# HC32F334JATI register map
File version: 1.0
CPU: CM4 r0p1, little endian, MPU, FPU, 4 interrupt priority bits
Registers are 32-bit, read-write, reset 0x0 unless marked. A register's access mark holds for its fields unless they carry their own. Offsets are from the block's base; [hi:lo] are bit positions; {n}, {i} and the like mark numbered series.

## CRC
Base 0x40008C00
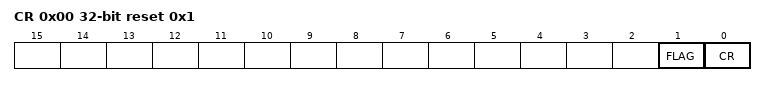
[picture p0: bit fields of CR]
0x00 CR reset 0x1
  [1] FLAG ro, [0] CR
0x04 RESLT
{0x80+4i} DAT{i} wo (i=0..31)

## CTC
Base 0x40049C00
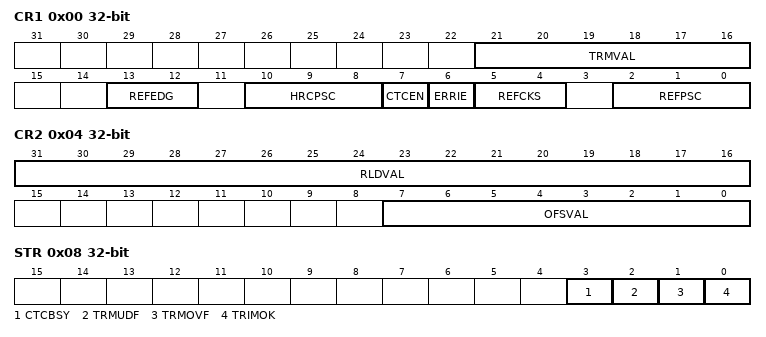
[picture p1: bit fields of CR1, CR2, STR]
0x00 CR1
  [21:16] TRMVAL, [13:12] REFEDG, [10:8] HRCPSC, [7] CTCEN, [6] ERRIE, [5:4] REFCKS, [2:0] REFPSC
0x04 CR2
  [31:16] RLDVAL, [7:0] OFSVAL
0x08 STR ro
  [3] CTCBSY, [2] TRMUDF, [1] TRMOVF, [0] TRIMOK
0x0C CNT 16-bit ro

## DAC1 — desc DAC
Base 0x40041000
Same registers: DAC2 0x40041400
0x00 DADR1 16-bit
0x02 DADR2 16-bit
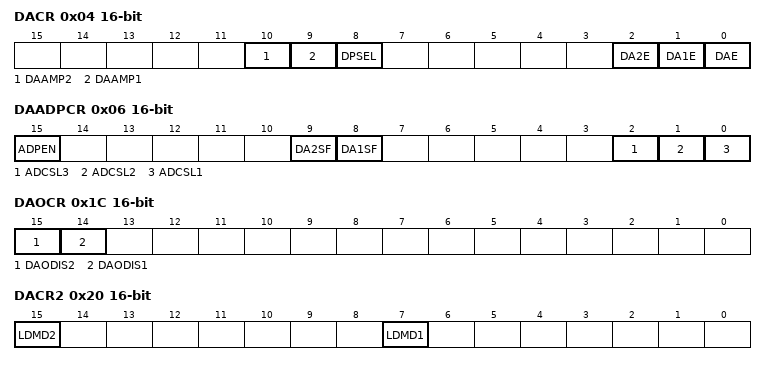
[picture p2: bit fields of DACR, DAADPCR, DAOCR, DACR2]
0x04 DACR 16-bit
  [10] DAAMP2, [9] DAAMP1, [8] DPSEL, [2] DA2E, [1] DA1E, [0] DAE
0x06 DAADPCR 16-bit
  [15] ADPEN, [9] DA2SF ro, [8] DA1SF ro, [2] ADCSL3, [1] ADCSL2, [0] ADCSL1
0x1C DAOCR 16-bit
  [15] DAODIS2, [14] DAODIS1
0x20 DACR2 16-bit
  [15] LDMD2, [7] LDMD1
0x2C DADACTR1 16-bit ro
  [11:0] DATAACT
0x2E DADACTR2 16-bit ro
  [11:0] DATAACT

## DBGC
Base 0xE0042000
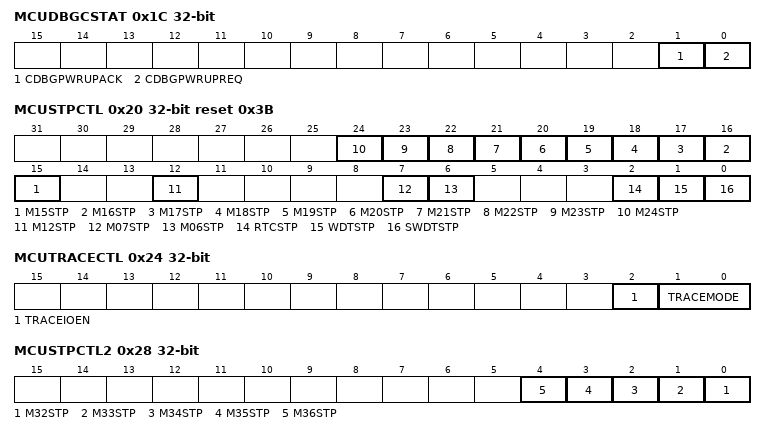
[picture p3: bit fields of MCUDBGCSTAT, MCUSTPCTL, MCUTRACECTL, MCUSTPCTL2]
0x1C MCUDBGCSTAT
  [1] CDBGPWRUPACK, [0] CDBGPWRUPREQ
0x20 MCUSTPCTL reset 0x3B
  [n] M{n}STP (n=15..24), [12] M12STP, [7] M07STP, [6] M06STP, [2] RTCSTP, [1] WDTSTP, [0] SWDTSTP
0x24 MCUTRACECTL
  [2] TRACEIOEN, [1:0] TRACEMODE
0x28 MCUSTPCTL2
  [n-32] M{n}STP (n=32..36)

## DMA
Base 0x40053000
0x00 EN
  [0] EN
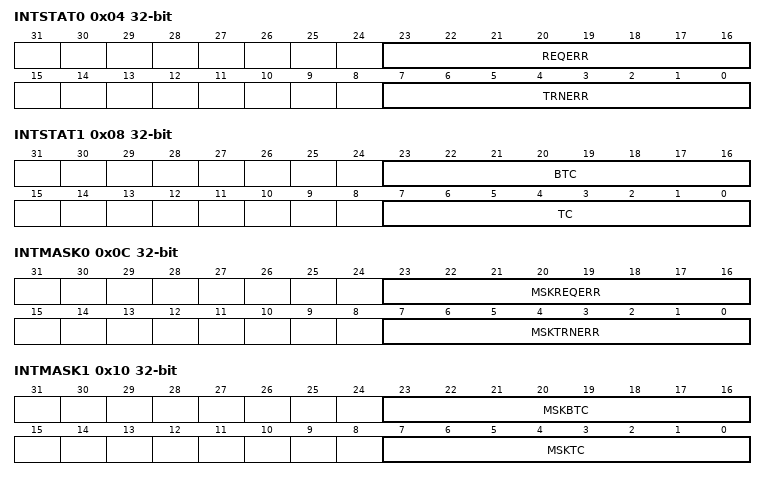
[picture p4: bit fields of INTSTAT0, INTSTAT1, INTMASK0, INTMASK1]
0x04 INTSTAT0 ro
  [23:16] REQERR, [7:0] TRNERR
0x08 INTSTAT1 ro
  [23:16] BTC, [7:0] TC
0x0C INTMASK0
  [23:16] MSKREQERR, [7:0] MSKTRNERR
0x10 INTMASK1
  [23:16] MSKBTC, [7:0] MSKTC
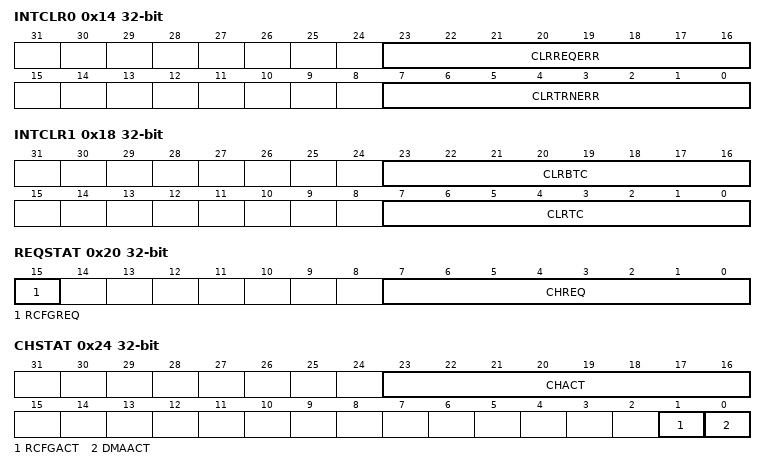
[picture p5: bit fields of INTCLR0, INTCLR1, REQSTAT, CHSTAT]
0x14 INTCLR0
  [23:16] CLRREQERR, [7:0] CLRTRNERR
0x18 INTCLR1
  [23:16] CLRBTC, [7:0] CLRTC
0x1C CHEN
  [7:0] CHEN
0x20 REQSTAT ro
  [15] RCFGREQ, [7:0] CHREQ
0x24 CHSTAT ro
  [23:16] CHACT, [1] RCFGACT, [0] DMAACT
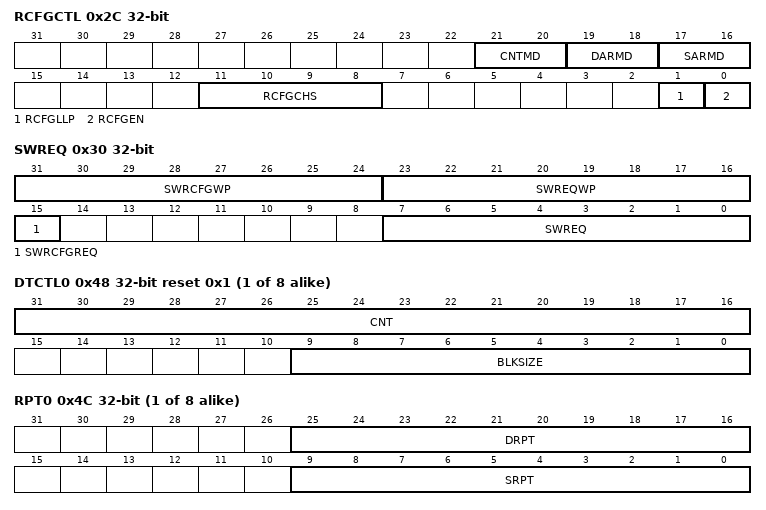
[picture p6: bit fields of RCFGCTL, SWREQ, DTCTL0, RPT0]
0x2C RCFGCTL
  [21:20] CNTMD, [19:18] DARMD, [17:16] SARMD, [11:8] RCFGCHS, [1] RCFGLLP, [0] RCFGEN
0x30 SWREQ
  [31:24] SWRCFGWP, [23:16] SWREQWP, [15] SWRCFGREQ, [7:0] SWREQ
0x34 CHENCLR wo
  [7:0] CHENCLR
{0x40+0x40*i} SAR{i} (i=0..7)
{0x44+0x40*i} DAR{i} (i=0..7)
{0x48+0x40*i} DTCTL{i} reset 0x1 (i=0..7)
  [31:16] CNT, [9:0] BLKSIZE
{0x4C+0x40*i} RPT{i} (i=0..7)
  [25:16] DRPT, [9:0] SRPT
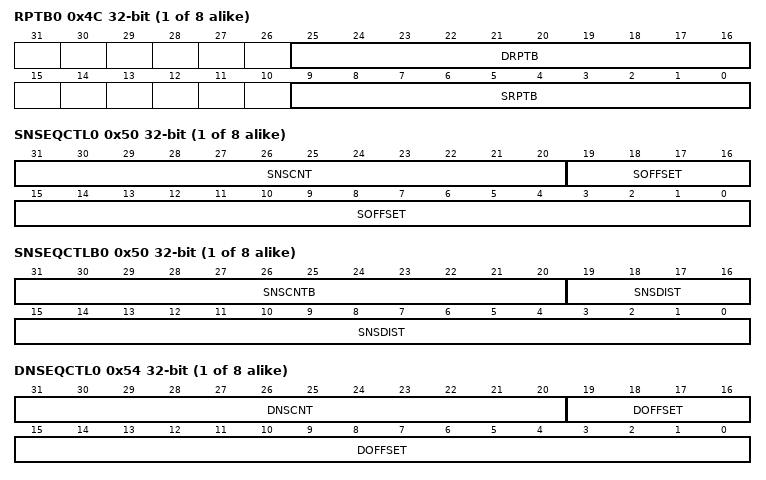
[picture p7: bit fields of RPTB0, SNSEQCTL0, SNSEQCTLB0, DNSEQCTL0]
{0x4C+0x40*i} RPTB{i} (alternate view of RPT{i}) (i=0..7)
  [25:16] DRPTB, [9:0] SRPTB
{0x50+0x40*i} SNSEQCTL{i} (i=0..7)
  [31:20] SNSCNT, [19:0] SOFFSET
{0x50+0x40*i} SNSEQCTLB{i} (alternate view of SNSEQCTL{i}) (i=0..7)
  [31:20] SNSCNTB, [19:0] SNSDIST
{0x54+0x40*i} DNSEQCTL{i} (i=0..7)
  [31:20] DNSCNT, [19:0] DOFFSET
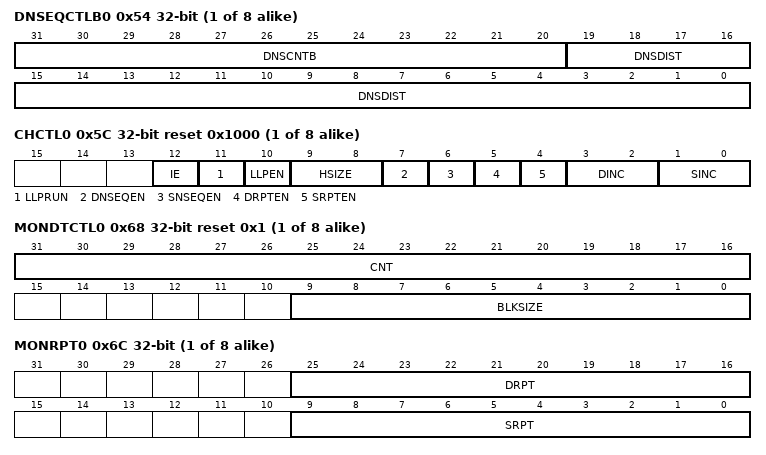
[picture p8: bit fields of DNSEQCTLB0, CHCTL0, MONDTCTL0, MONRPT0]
{0x54+0x40*i} DNSEQCTLB{i} (alternate view of DNSEQCTL{i}) (i=0..7)
  [31:20] DNSCNTB, [19:0] DNSDIST
{0x58+0x40*i} LLP{i} (i=0..7)
  [31:2] LLP
{0x5C+0x40*i} CHCTL{i} reset 0x1000 (i=0..7)
  [12] IE, [11] LLPRUN, [10] LLPEN, [9:8] HSIZE, [7] DNSEQEN, [6] SNSEQEN, [5] DRPTEN, [4] SRPTEN, [3:2] DINC, [1:0] SINC
{0x60+0x40*i} MONSAR{i} ro (i=0..7)
{0x64+0x40*i} MONDAR{i} ro (i=0..7)
{0x68+0x40*i} MONDTCTL{i} ro reset 0x1 (i=0..7)
  [31:16] CNT, [9:0] BLKSIZE
{0x6C+0x40*i} MONRPT{i} ro (i=0..7)
  [25:16] DRPT, [9:0] SRPT
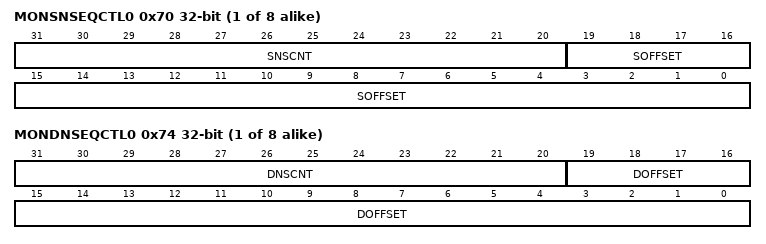
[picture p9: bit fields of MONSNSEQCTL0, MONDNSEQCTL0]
{0x70+0x40*i} MONSNSEQCTL{i} ro (i=0..7)
  [31:20] SNSCNT, [19:0] SOFFSET
{0x74+0x40*i} MONDNSEQCTL{i} ro (i=0..7)
  [31:20] DNSCNT, [19:0] DOFFSET

## EFM
Base 0x40010400
0x00 FAPRT
  [15:0] FAPRT
0x04 KEY1
0x08 KEY2
0x14 FSTP
  [0] FSTP
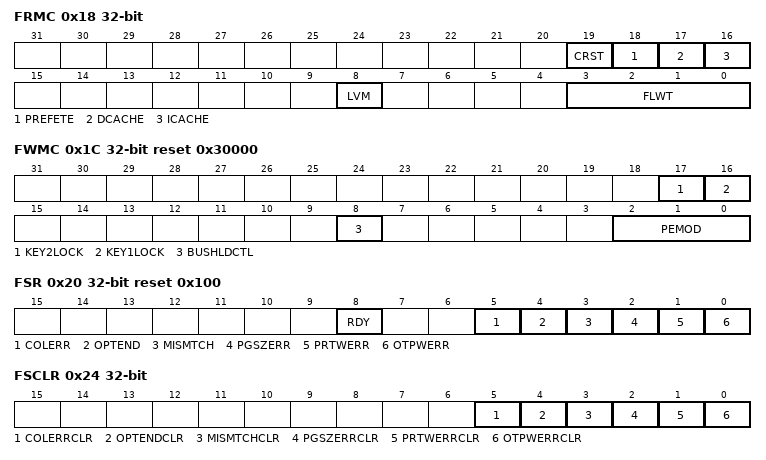
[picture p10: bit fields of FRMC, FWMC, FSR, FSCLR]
0x18 FRMC
  [19] CRST, [18] PREFETE, [17] DCACHE, [16] ICACHE, [8] LVM, [3:0] FLWT
0x1C FWMC reset 0x30000
  [17] KEY2LOCK, [16] KEY1LOCK, [8] BUSHLDCTL, [2:0] PEMOD
0x20 FSR ro reset 0x100
  [8] RDY, [5] COLERR, [4] OPTEND, [3] MISMTCH, [2] PGSZERR, [1] PRTWERR, [0] OTPWERR
0x24 FSCLR
  [5] COLERRCLR, [4] OPTENDCLR, [3] MISMTCHCLR, [2] PGSZERRCLR, [1] PRTWERRCLR, [0] OTPWERRCLR
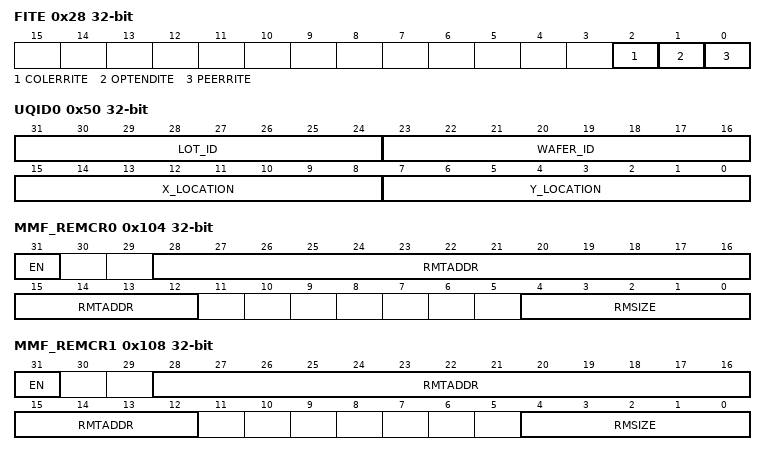
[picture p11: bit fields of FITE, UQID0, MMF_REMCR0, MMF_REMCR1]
0x28 FITE
  [2] COLERRITE, [1] OPTENDITE, [0] PEERRITE
0x2C FSWP ro
  [0] FSWP
0x40 CHIPID ro reset 0x58480334
0x50 UQID0 ro
  [31:24] LOT_ID, [23:16] WAFER_ID, [15:8] X_LOCATION, [7:0] Y_LOCATION
0x54 UQID1 ro
  [31:0] LOT_ID
0x58 UQID2 ro
  [7:0] LOT_ID
0x100 MMF_REMPRT
  [15:0] MMF_REMPRT
0x104 MMF_REMCR0
  [31] EN, [28:12] RMTADDR, [4:0] RMSIZE
0x108 MMF_REMCR1
  [31] EN, [28:12] RMTADDR, [4:0] RMSIZE
0x10C MMF_REMCR2 ro reset 0x1
  [0] MAPSEL
0x180 WLOCK
  [0] WLOCK0
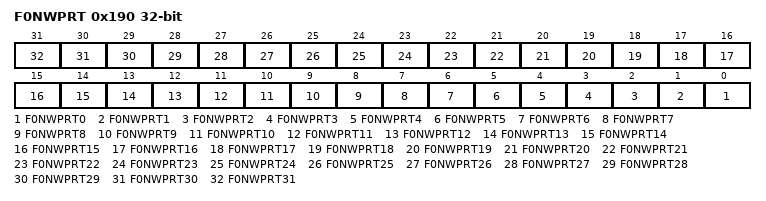
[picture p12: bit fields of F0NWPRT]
0x190 F0NWPRT
  [n] F0NWPRT{n} (n=0..31)
